# apollo510 register map
Vendor: Ambiq Micro; Series: Apollo; File version: 1.0
CPU: CM55 r1p1, little endian, MPU, FPU, double-precision FPU, DSP, I-cache, D-cache, VTOR, ITCM, DTCM, 4 interrupt priority bits, 0 interrupts, 8 SAU regions
Registers are 32-bit, read-write, reset 0x0 unless marked. A register's access mark holds for its fields unless they carry their own. Offsets are from the block's base; [hi:lo] are bit positions; 'fields as' and 'values as' point back to an identical list.

## VCOMP — Voltage Comparator
Base 0x4000C000
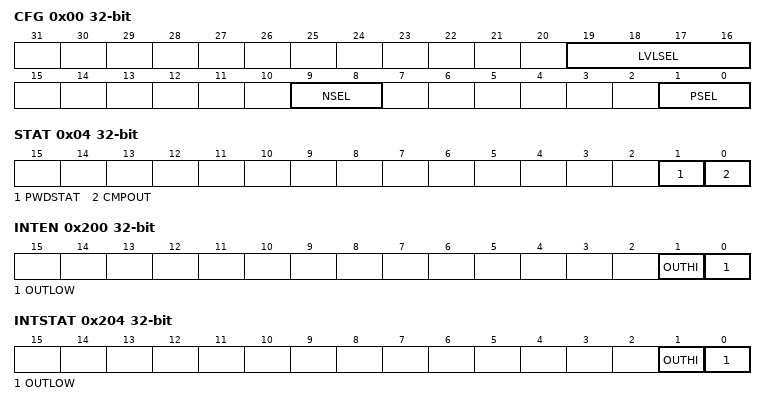
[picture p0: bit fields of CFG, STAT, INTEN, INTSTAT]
0x00 CFG — The Voltage Comparator Configuration Register contains the software control for selecting beween the 4 options for the positive input as well as the multiple options for the reference input.
  [19:16] LVLSEL — When the reference input NSEL is set to NSEL_DAC, this bitfield selects the voltage level for the negative input to the comparator.
    0=0P58V (Set Reference input to 0.58 Volts.); 1=0P77V (Set Reference input to 0.77 Volts.); 2=0P97V (Set Reference input to 0.97 Volts.); 3=1P16V (Set Reference input to 1.16 Volts.); 4=1P35V (Set Reference input to 1.35 Volts.); 5=1P55V (Set Reference input to 1.55 Volts.); 6=1P74V (Set Reference input to 1.74 Volts.); 7=1P93V (Set Reference input to 1.93 Volts.); 8=2P13V (Set Reference input to 2.13 Volts.)
  [9:8] NSEL — This bitfield selects the negative input to the comparator.
    0=VREFEXT1 (Use external reference 1 for reference input.); 1=VREFEXT2 (Use external reference 2 for reference input.); 2=VREFEXT3 (Use external reference 3 for reference input.); 3=DAC (Use DAC output selected by LVLSEL for reference input.)
  [1:0] PSEL — This bitfield selects the positive input to the comparator.
    0=VDDADJ (Use VDDADJ for the positive input.); 1=VTEMP (Use the temperature sensor output for the positive input. Note: If this channel is selected for PSEL, the bandap circuit required for temperature comparisons will automatically turn on. The bandgap circuit requires 11us to stabalize.); 2=VEXT1 (Use external voltage 0 for positive input.); 3=VEXT2 (Use external voltage 1 for positive input.)
0x04 STAT — Status
  [1] PWDSTAT — This bit indicates the power down state of the voltage comparator.
    1=POWERED_DOWN (The voltage comparator is powered down.); 0=POWERED_UP (The voltage comparator is powered up.)
  [0] CMPOUT — This bit is 1 if the positive input of the comparator is greater than the negative input.
    0=VOUT_LOW (The negative input of the comparator is greater than the positive input.); 1=VOUT_HIGH (The positive input of the comparator is greater than the negative input.)
0x08 PWDKEY — Write a value of 0x37 to unlock, write any other value to lock. This register also indicates lock status when read. When in the unlccked state (i.e. 0x37 has been written), it reads as 1. When in the locked state, it reads as 0.
  [31:0] PWDKEY — Key register value.
    55=Key (Key value to unlock the register.)
0x200 INTEN — Set bits in this register to allow this module to generate the corresponding interrupt.
  [1] OUTHI — This bit is the vcompout high interrupt.
  [0] OUTLOW — This bit is the vcompout low interrupt.
0x204 INTSTAT — Read bits from this register to discover the cause of a recent interrupt.
  fields as INTEN
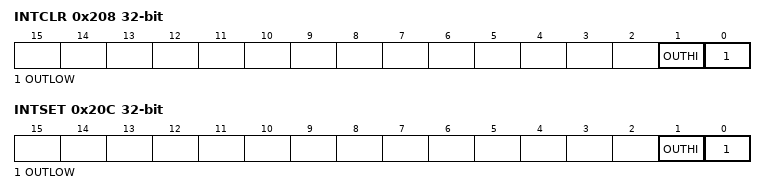
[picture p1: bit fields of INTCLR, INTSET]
0x208 INTCLR — Write a 1 to a bit in this register to clear the interrupt status associated with that bit.
  fields as INTEN
0x20C INTSET — Write a 1 to a bit in this register to instantly generate an interrupt from this module. (Generally used for testing purposes).
  fields as INTEN

## WDT — Watchdog Timer
Base 0x40024000
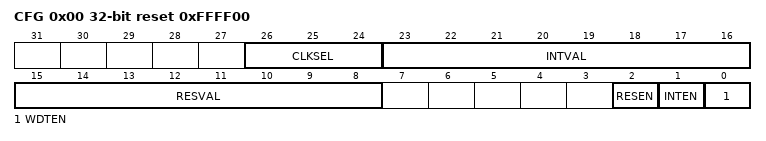
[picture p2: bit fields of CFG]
0x00 CFG reset 0xFFFF00 — This is the configuration register for the watch dog timer. It controls the enable, interrupt set, clocks for the timer, the compare values for the counters to trigger a reset or interrupt. This register can only be written to if the watch dog timer is unlocked (WDTLOCK is not set).
  [26:24] CLKSEL — Select the frequency for the WDT. All values not enumerated below are undefined.
    0=OFF (Low Power Mode. This setting disables the watch dog timer.); 1=LFRC_DIV8 (Clock source is LFRC / 8); 2=LFRC_DIV64 (Clock source is LFRC / 64); 3=LFRC_DIV1K (Clock source is LFRC / 1024); 4=LFRC_DIV16K (Clock source is LFRC / 16384); 5=XTAL_HS (High frequency XTAL); 6=XTAL_HS_DIV2 (High frequency XTAL divide by 2)
  [23:16] INTVAL — This bitfield is the compare value for counter bits 7:0 to generate a watchdog interrupt.
  [15:8] RESVAL — This bitfield is the compare value for counter bits 7:0 to generate a watchdog reset. This will cause a software reset.
  [2] RESEN — This bitfield enables the WDT reset. This needs to be set together with the WDREN bit in REG_RSTGEN_CFG register (in reset gen) to trigger the reset.
  [1] INTEN — This bitfield enables the WDT interrupt. Note : This bit must be set before the interrupt status bit will reflect a watchdog timer expiration. The IER interrupt register must also be enabled for a WDT interrupt to be sent to the NVIC.
  [0] WDTEN — This bitfield enables the WDT.
0x04 RSTRT — This register will Restart the watchdog timer. Writing a special key value into this register will result in the watch dog timer being reset, so that the count will start again. It is expected that the software will periodically write to this register to indicate that the system is functional. The watch dog timer can continue running when the system is in deep sleep, and the interrupt will trigger the wake. After the wake, the core can reset the watch dog timer.
  [7:0] RSTRT — Writing 0xB2 to WDTRSTRT restarts the watchdog timer. This is a write only register. Reading this register will only provide all 0.
    178=KEYVALUE (This is the key value to write to WDTRSTRT to restart the WDT. This is a write only register.); 0=DEFAULT (Default/Reset value. This is a write only register.)
0x08 LOCK — This register locks the watch dog timer. Once it is locked, the configuration register (WDTCFG) for watch dog timer cannot be written to.
  [7:0] LOCK — Writing 0x3A locks the watchdog timer. Once locked, the WDTCFG reg cannot be written and WDTEN is set.
    58=KEYVALUE (This is the key value to write to WDTLOCK to lock the WDT.); 0=DEFAULT (Default/Reset value.)
0x0C COUNT — This register holds the current count for the watch dog timer. This is a read only register. SW cannot set the value in the counter, but can reset it.
  [7:0] COUNT — Read-Only current value of the WDT counter
0x200 WDTIEREN — Set bits in this register to allow this module to generate the corresponding interrupt.
  [0] WDTINT — Watchdog Timer Interrupt.
0x204 WDTIERSTAT — Read bits from this register to discover the cause of a recent interrupt.
  [0] WDTINT — Watchdog Timer Interrupt.
0x208 WDTIERCLR — Write a 1 to a bit in this register to clear the interrupt status associated with that bit.
  [0] WDTINT — Watchdog Timer Interrupt.
0x20C WDTIERSET — Write a 1 to a bit in this register to instantly generate an interrupt from this module. (Generally used for testing purposes).
  [0] WDTINT — Watchdog Timer Interrupt.
